# GT32U2086 register map
Vendor: FPTTelecom
Registers are 32-bit, read-write, reset 0x0 unless marked. A register's access mark holds for its fields unless they carry their own. Offsets are from the block's base; [hi:lo] are bit positions; lines under a group give offsets from that group; 'fields as' and 'values as' point back to an identical list.

## SYSCSR — SYSCSR - SYSTEM CONTROL AND STATUS REGISTERS SYSCSR : 0x44010000 - 0x4401FFFF (64 KB) Reference: GT32U2086_SYSCSR_v4.xlsx
Base 0x44010000
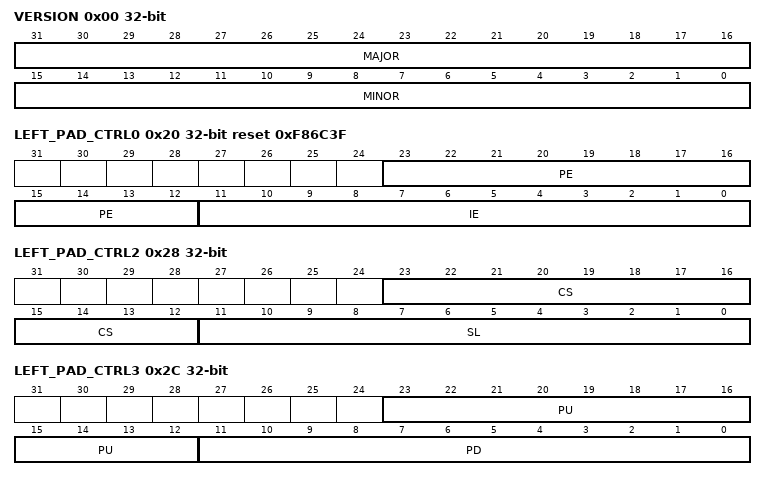
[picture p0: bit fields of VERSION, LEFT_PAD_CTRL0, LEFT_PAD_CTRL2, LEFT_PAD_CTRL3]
0x00 VERSION ro — SYSCSR Version bit[15:0] MINOR | bit[31:16] MAJOR
  [31:16] MAJOR — Major version number in bits [31:16]
  [15:0] MINOR — Minor version number in bits [15:0]
0x10 LEFT_IO_CFG — IO Mux Register: 16 two-bit fields in bit[31:0]
  [31:0] MODE — Sixteen 2-bit mux fields; field n is located at 2*n
0x14 BOT_IO_CFG — IO Mux Register: 16 two-bit fields in bit[31:0]
  [31:0] MODE — Sixteen 2-bit mux fields; field n is located at 2*n
0x18 RIGHT_IO_CFG — IO Mux Register: 16 two-bit fields in bit[31:0]
  [31:0] MODE — Sixteen 2-bit mux fields; field n is located at 2*n
0x1C TOP_IO_CFG — IO Mux Register: 16 two-bit fields in bit[31:0]
  [31:0] MODE — Sixteen 2-bit mux fields; field n is located at 2*n
0x20 LEFT_PAD_CTRL0 reset 0xF86C3F — Pad Control Register bit[11:0] IE | bit[23:12] PE (active-low pull enable)
  [23:12] PE — Pull-cell control active-low: 0=enabled, 1=disabled
  [11:0] IE — Enable the digital input path, one bit per pad
0x24 LEFT_PAD_CTRL1 reset 0xFFFFFF — Pad Control Register bit[11:0] DS
  [11:0] DS — Coarse drive strength: 0=low, 1=high
0x28 LEFT_PAD_CTRL2 — Pad Control Register bit[11:0] SL | bit[23:12] CS
  [23:12] CS — Schmitt trigger: 0=disabled, 1=enabled
  [11:0] SL — Slew rate: 0=slow, 1=fast
0x2C LEFT_PAD_CTRL3 — Pad Control Register bit[11:0] PD | bit[23:12] PU
  [23:12] PU — Select pull-up, one bit per pad
  [11:0] PD — Select pull-down, one bit per pad
0x30 LEFT_PAD_CTRL4 — Pad Control Register bit[23:0] PDRV (2 bits per pin)
  [23:0] PDRV — 2-bit drive-current fields: 00=2mA, 01=4mA, 10=8mA, 11=12mA
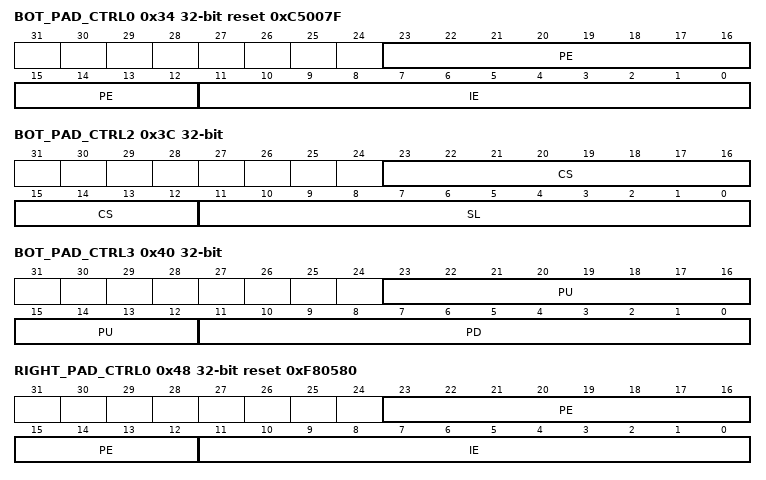
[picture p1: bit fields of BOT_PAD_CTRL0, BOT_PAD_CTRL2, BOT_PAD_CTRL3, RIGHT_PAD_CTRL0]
0x34 BOT_PAD_CTRL0 reset 0xC5007F — Pad Control Register bit[11:0] IE | bit[23:12] PE (active-low pull enable)
  fields as LEFT_PAD_CTRL0
0x38 BOT_PAD_CTRL1 reset 0xFFFFFF — Pad Control Register bit[11:0] DS
  [11:0] DS — Coarse drive strength: 0=low, 1=high
0x3C BOT_PAD_CTRL2 — Pad Control Register bit[11:0] SL | bit[23:12] CS
  fields as LEFT_PAD_CTRL2
0x40 BOT_PAD_CTRL3 — Pad Control Register bit[11:0] PD | bit[23:12] PU
  fields as LEFT_PAD_CTRL3
0x44 BOT_PAD_CTRL4 — Pad Control Register bit[23:0] PDRV (2 bits per pin)
  fields as LEFT_PAD_CTRL4
0x48 RIGHT_PAD_CTRL0 reset 0xF80580 — Pad Control Register bit[11:0] IE | bit[23:12] PE (active-low pull enable)
  fields as LEFT_PAD_CTRL0
0x4C RIGHT_PAD_CTRL1 reset 0xFFFFFF — Pad Control Register bit[11:0] DS
  [11:0] DS — Coarse drive strength: 0=low, 1=high
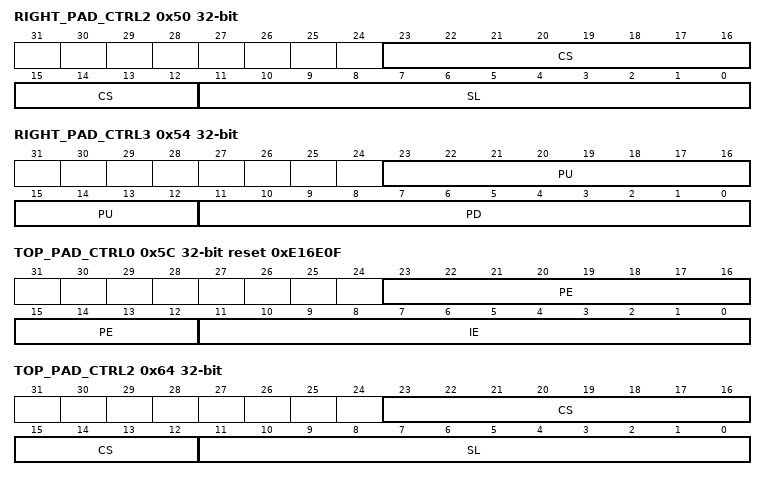
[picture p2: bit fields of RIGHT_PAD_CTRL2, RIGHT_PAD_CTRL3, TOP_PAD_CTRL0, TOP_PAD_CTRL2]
0x50 RIGHT_PAD_CTRL2 — Pad Control Register bit[11:0] SL | bit[23:12] CS
  fields as LEFT_PAD_CTRL2
0x54 RIGHT_PAD_CTRL3 — Pad Control Register bit[11:0] PD | bit[23:12] PU
  fields as LEFT_PAD_CTRL3
0x58 RIGHT_PAD_CTRL4 — Pad Control Register bit[23:0] PDRV (2 bits per pin)
  fields as LEFT_PAD_CTRL4
0x5C TOP_PAD_CTRL0 reset 0xE16E0F — Pad Control Register bit[11:0] IE | bit[23:12] PE (active-low pull enable)
  fields as LEFT_PAD_CTRL0
0x60 TOP_PAD_CTRL1 reset 0xFFFFFF — Pad Control Register bit[11:0] DS
  [11:0] DS — Coarse drive strength: 0=low, 1=high
0x64 TOP_PAD_CTRL2 — Pad Control Register bit[11:0] SL | bit[23:12] CS
  fields as LEFT_PAD_CTRL2
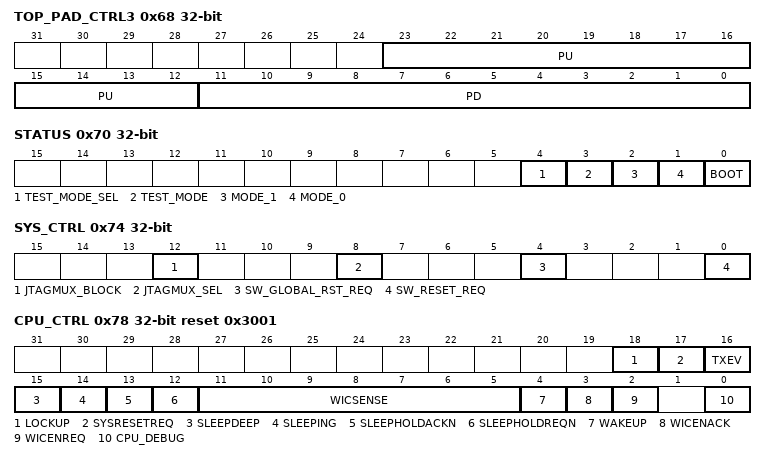
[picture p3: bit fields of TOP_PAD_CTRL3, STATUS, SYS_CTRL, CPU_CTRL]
0x68 TOP_PAD_CTRL3 — Pad Control Register bit[11:0] PD | bit[23:12] PU
  fields as LEFT_PAD_CTRL3
0x6C TOP_PAD_CTRL4 — Pad Control Register bit[23:0] PDRV (2 bits per pin)
  fields as LEFT_PAD_CTRL4
0x70 STATUS ro — SYSCSR Status: BOOT[0], MODE_0[1], MODE_1[2], TEST_MODE[3], TEST_MODE_SEL[4]
  [4] TEST_MODE_SEL — Sampled TEST_MODE_SEL pin value
  [3] TEST_MODE — Sampled TEST_MODE pin value
  [2] MODE_1 — Sampled MODE_1 pin value
  [1] MODE_0 — Sampled MODE_0 pin value
  [0] BOOT — Sampled BOOT pin value
0x74 SYS_CTRL — System Control: sw_reset_req bit[0] SW_RESET_REQ | bit[4] SW_GLOBAL_RST_REQ | bit[8] JTAGMUX_SEL | bit[12] JTAGMUX_BLOCK
  [12] JTAGMUX_BLOCK — Lock the JTAG mux as defined by the GT32U2086 LL
  [8] JTAGMUX_SEL — Select the JTAG mux path
  [4] SW_GLOBAL_RST_REQ — Send a global-reset request
  [0] SW_RESET_REQ — Send a software-reset request to the CRM
0x78 CPU_CTRL reset 0x3001 — CPU WIC Logic Control bit[0] CPU_DEBUG | bit[2] WICENREQ | bit[3] WICENACK | bit[4] WAKEUP | bit[11:5] WICSENSE | bit[12] SLEEPHOLDREQN | bit[13] SLEEPHOLDACKN | bit[14] SLEEPING | bit[15] SLEEPDEEP | bit[16] TXEV | bit[17] SYSRESETREQ | bit[18] LOCKUP; only bits [0], [2], [12] are RW; remaining named fields are RO
  [18] LOCKUP — CPU is in the lockup state
  [17] SYSRESETREQ — System-reset request from the CPU
  [16] TXEV — Event pulse generated by the SEV instruction
  [15] SLEEPDEEP — CPU is in the deep-sleep state
  [14] SLEEPING — CPU is in the idle/sleep state
  [13] SLEEPHOLDACKN — Active-low sleep-state hold acknowledgment
  [12] SLEEPHOLDREQN — Active-low sleep-state hold request
  [11:5] WICSENSE — WIC wake-up sense lines in bits [11:5]
  [4] WAKEUP — CPU wake-up status
  [3] WICENACK — CPU acknowledgment of the WIC enable request
  [2] WICENREQ — Request WIC enable from the CPU
  [0] CPU_DEBUG — Suppress watchdog reset/interrupt in debug mode
0x7C CPU_SYSTICK reset 0x1869F — CPU SysTick calibration value
  [23:0] TENMS — Number of core-clock ticks in 10 ms
0x80 OSC_PAD_CTRL reset 0x13 — Oscillator pad control bits[5:0]
  [5:0] CONTROL — Raw oscillator pad control
0x88 ROM_CTRL — ROM control
  [0] ENABLE — ROM control enable
0x8C LEFT_PAD_CTRL5 reset 0xF8041F — Left pad control group 5 bits[23:0]
  [23:0] VALUE — Raw v11 field
0x90 LEFT_PAD_CTRL6 — Left pad control group 6 bits[23:0]
  [23:0] VALUE — Raw v11 field
0x94 LEFT_PAD_CTRL7 — Left pad control group 7 bits[23:0]
  [23:0] VALUE — Raw v11 field
0x98 BOT_PAD_CTRL5 reset 0xC7007F — Bottom pad control group 5 bits[23:0]
  [23:0] VALUE — Raw v11 field
0x9C BOT_PAD_CTRL6 — Bottom pad control group 6 bits[23:0]
  [23:0] VALUE — Raw v11 field
0xA0 BOT_PAD_CTRL7 — Bottom pad control group 7 bits[23:0]
  [23:0] VALUE — Raw v11 field
0xA4 RIGHT_PAD_CTRL5 reset 0xF80180 — Right pad control group 5 bits[23:0]
  [23:0] VALUE — Raw v11 field
0xA8 RIGHT_PAD_CTRL6 — Right pad control group 6 bits[23:0]
  [23:0] VALUE — Raw v11 field
0xAC RIGHT_PAD_CTRL7 — Right pad control group 7 bits[23:0]
  [23:0] VALUE — Raw v11 field
0xB0 TOP_PAD_CTRL5 reset 0xE1E007 — Top pad control group 5 bits[23:0]
  [23:0] VALUE — Raw v11 field
0xB4 TOP_PAD_CTRL6 — Top pad control group 6 bits[23:0]
  [23:0] VALUE — Raw v11 field
0xB8 TOP_PAD_CTRL7 — Top pad control group 7 bits[23:0]
  [23:0] VALUE — Raw v11 field
0xBC LEFT_IO_CFG_EXT — Left mux selectors for die-pad indexes 16..23
  [15:0] VALUE — Eight 2-bit mux selectors
0xC0 BOT_IO_CFG_EXT — Bottom mux selectors for die-pad indexes 16..23
  [15:0] VALUE — Eight 2-bit mux selectors
0xC4 RIGHT_IO_CFG_EXT — Right mux selectors for die-pad indexes 16..23
  [15:0] VALUE — Eight 2-bit mux selectors
0xC8 TOP_IO_CFG_EXT — Top mux selectors for die-pad indexes 16..23
  [15:0] VALUE — Eight 2-bit mux selectors
